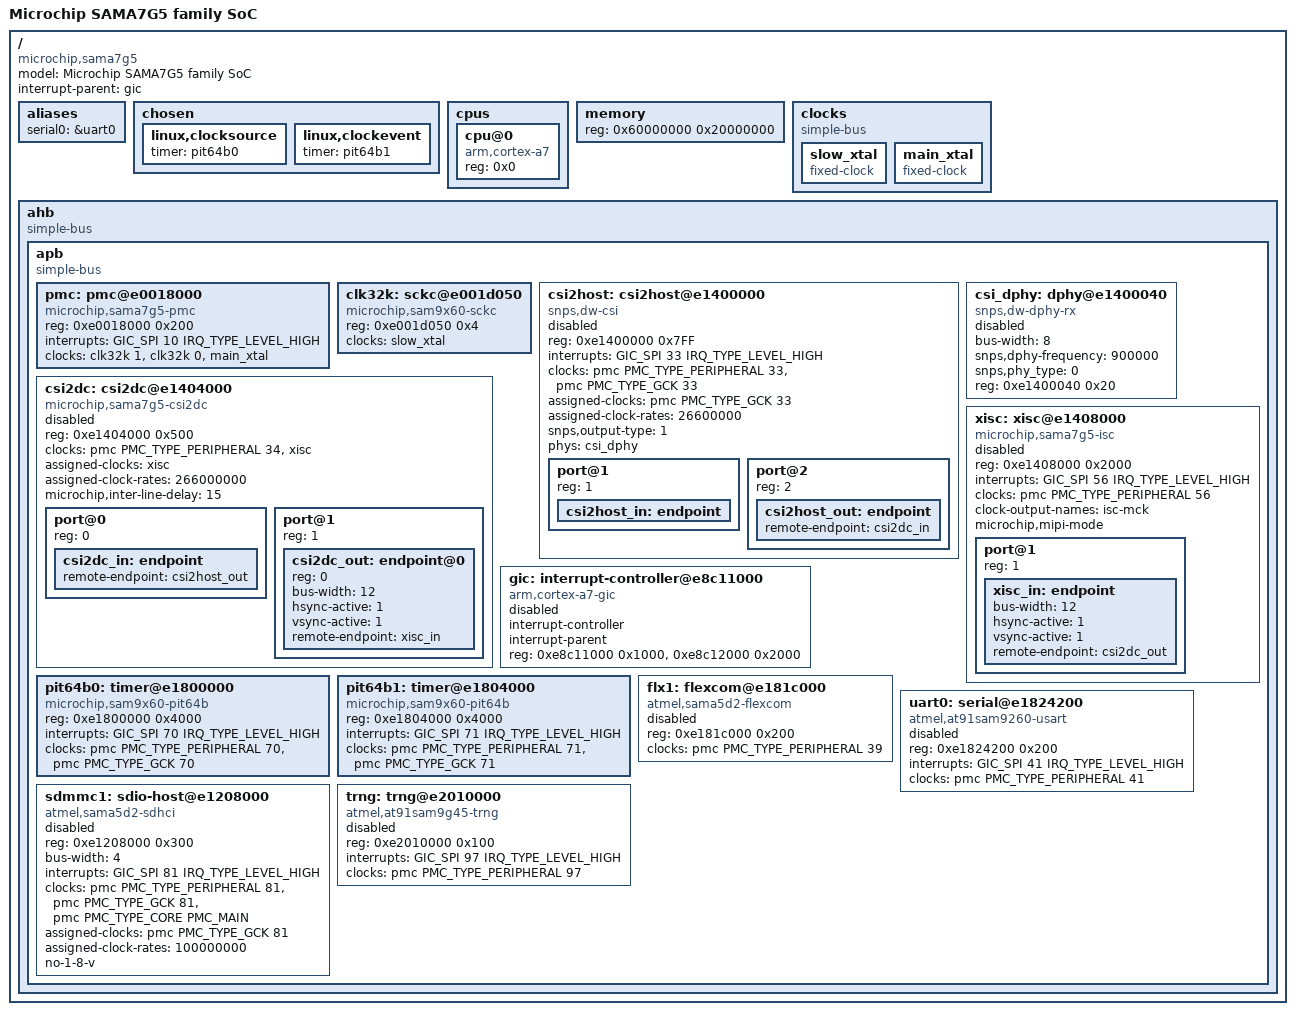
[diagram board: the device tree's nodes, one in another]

// SPDX-License-Identifier: (GPL-2.0+ OR MIT)
/*
 * sama7g5.dtsi - Device Tree Include file for SAMA7G5 family SoC
 *
 *  Copyright (C) 2020 Microchip Technology, Inc. and its subsidiaries
 *
 *  Author: Eugen Hristev <eugen.hristev@microchip.com>
 *
 */

#include <dt-bindings/interrupt-controller/irq.h>
#include <dt-bindings/interrupt-controller/arm-gic.h>
#include <dt-bindings/clock/at91.h>
#include <dt-bindings/dma/at91.h>
#include <dt-bindings/gpio/gpio.h>

/ {
	model = "Microchip SAMA7G5 family SoC";
	compatible = "microchip,sama7g5";
	#address-cells = <1>;
	#size-cells = <1>;
	interrupt-parent = <&gic>;

	aliases {
		serial0 = &uart0;
	};

	chosen {
		linux,clocksource {
			timer=<&pit64b0>;
		};

		linux,clockevent {
			timer=<&pit64b1>;
		};
	};

	cpus {
		#address-cells = <1>;
		#size-cells = <0>;

		cpu@0 {
			device_type = "cpu";
			compatible = "arm,cortex-a7";
			reg = <0x0>;
		};
	};

	/* 512 M */
	memory {
		device_type = "memory";
		reg = <0x60000000 0x20000000>;
	};

	clocks {
		compatible = "simple-bus";
		#address-cells = <1>;
		#size-cells = <0>;

		slow_xtal: slow_xtal {
			compatible = "fixed-clock";
			#clock-cells = <0>;
		};

		main_xtal: main_xtal {
			compatible = "fixed-clock";
			#clock-cells = <0>;
		};
	};

	ahb {
		compatible = "simple-bus";
		#address-cells = <1>;
		#size-cells = <1>;
		ranges;

		apb {
			compatible = "simple-bus";
			#address-cells = <1>;
			#size-cells = <1>;
			ranges;

			pmc: pmc@e0018000 {
				compatible = "microchip,sama7g5-pmc", "syscon";
				reg = <0xe0018000 0x200>;
				interrupts = <GIC_SPI 10 IRQ_TYPE_LEVEL_HIGH>;
				#clock-cells = <2>;
				clocks = <&clk32k 1>, <&clk32k 0>, <&main_xtal>;
				clock-names = "td_slck", "md_slck", "main_xtal";
			};

			clk32k: sckc@e001d050 {
				compatible = "microchip,sam9x60-sckc";
				reg = <0xe001d050 0x4>;
				clocks = <&slow_xtal>;
				#clock-cells = <1>;
			};

			csi2host: csi2host@e1400000 {
				compatible = "snps,dw-csi";
				#address-cells = <1>;
				#size-cells = <0>;
				reg = <0xe1400000 0x7FF>;
				interrupts = <GIC_SPI 33 IRQ_TYPE_LEVEL_HIGH>;
				clocks = <&pmc PMC_TYPE_PERIPHERAL 33>, <&pmc PMC_TYPE_GCK 33>;
				clock-names = "perclk", "phyclk";
				assigned-clocks = <&pmc PMC_TYPE_GCK 33>;
				assigned-clock-rates = <26600000>;
				snps,output-type = <1>;
				phys = <&csi_dphy>;
				status = "disabled";

				port@1 {
					reg = <1>;
					csi2host_in: endpoint {
					};
				};

				port@2 {
					reg = <2>;
					csi2host_out: endpoint {
						remote-endpoint = <&csi2dc_in>;
					};
				};
			};

			csi_dphy: dphy@e1400040 {
				compatible = "snps,dw-dphy-rx";
				#phy-cells = <0>;
				bus-width = <8>;
				snps,dphy-frequency = <900000>;
				snps,phy_type = <0>;
				reg = <0xe1400040 0x20>;
				status = "disabled";
			};

			csi2dc: csi2dc@e1404000 {
				compatible = "microchip,sama7g5-csi2dc";
				#address-cells = <1>;
				#size-cells = <0>;
				reg = <0xe1404000 0x500>;
				clocks = <&pmc PMC_TYPE_PERIPHERAL 34>, <&xisc>;
				clock-names = "pclk", "scck";
				assigned-clocks = <&xisc>;
				assigned-clock-rates = <266000000>;
				microchip,inter-line-delay = <15>;
				status = "disabled";

				port@0 {
					reg = <0>;
					csi2dc_in: endpoint {
						remote-endpoint = <&csi2host_out>;
					};
				};

				port@1 {
					#address-cells = <1>;
					#size-cells = <0>;
					reg = <1>;
					csi2dc_out: endpoint@0 {
						reg = <0>; /* VC 0 */
						bus-width = <12>;
						hsync-active = <1>;
						vsync-active = <1>;
						remote-endpoint = <&xisc_in>;
					};
				};
			};

			xisc: xisc@e1408000 {
				compatible = "microchip,sama7g5-isc";
				reg = <0xe1408000 0x2000>;
				interrupts = <GIC_SPI 56 IRQ_TYPE_LEVEL_HIGH>;
				#address-cells = <1>;
				#size-cells = <0>;
				clocks = <&pmc PMC_TYPE_PERIPHERAL 56>;
				clock-names = "hclock";
				#clock-cells = <0>;
				clock-output-names = "isc-mck";
				microchip,mipi-mode;
				status = "disabled";

				port@1 {
					reg = <1>;
					xisc_in: endpoint {
						bus-width = <12>;
						hsync-active = <1>;
						vsync-active = <1>;
						remote-endpoint = <&csi2dc_out>;
					};
				};
			};

			gic: interrupt-controller@e8c11000 {
				compatible = "arm,cortex-a7-gic";
				#interrupt-cells = <3>;
				#address-cells = <0>;
				interrupt-controller;
				interrupt-parent;
				reg = <0xe8c11000 0x1000>,
					<0xe8c12000 0x2000>;
				status = "disabled";
			};

			pit64b0: timer@e1800000 {
				compatible = "microchip,sam9x60-pit64b";
				reg = <0xe1800000 0x4000>;
				interrupts = <GIC_SPI 70 IRQ_TYPE_LEVEL_HIGH>;
				clocks = <&pmc PMC_TYPE_PERIPHERAL 70>, <&pmc PMC_TYPE_GCK 70>;
				clock-names = "pclk", "gclk";
				status = "okay";
			};

			pit64b1: timer@e1804000 {
				compatible = "microchip,sam9x60-pit64b";
				reg = <0xe1804000 0x4000>;
				interrupts = <GIC_SPI 71 IRQ_TYPE_LEVEL_HIGH>;
				clocks = <&pmc PMC_TYPE_PERIPHERAL 71>, <&pmc PMC_TYPE_GCK 71>;
				clock-names = "pclk", "gclk";
				status = "okay";
			};

			flx1: flexcom@e181c000 {
				compatible = "atmel,sama5d2-flexcom";
				reg = <0xe181c000 0x200>;
				clocks = <&pmc PMC_TYPE_PERIPHERAL 39>;
				#address-cells = <1>;
				#size-cells = <1>;
				ranges = <0x0 0xe181c000 0x800>;
				status = "disabled";
			};

			uart0: serial@e1824200 {
				compatible = "atmel,at91sam9260-usart";
				reg = <0xe1824200 0x200>;
				interrupts = <GIC_SPI 41 IRQ_TYPE_LEVEL_HIGH>;
				clocks = <&pmc PMC_TYPE_PERIPHERAL 41>;
				clock-names = "usart";
				status = "disabled";
			};

			sdmmc1: sdio-host@e1208000 {
				compatible = "atmel,sama5d2-sdhci";
				reg = <0xe1208000 0x300>;
				bus-width = <4>;
				interrupts = <GIC_SPI 81 IRQ_TYPE_LEVEL_HIGH>;
				clocks = <&pmc PMC_TYPE_PERIPHERAL 81>, <&pmc PMC_TYPE_GCK 81>, <&pmc PMC_TYPE_CORE PMC_MAIN>;
				clock-names = "hclock", "multclk", "baseclk";
				assigned-clocks = <&pmc PMC_TYPE_GCK 81>;
				assigned-clock-rates = <100000000>;
				no-1-8-v;
				status = "disabled";
			};

			trng: trng@e2010000 {
				compatible = "atmel,at91sam9g45-trng";
				reg = <0xe2010000 0x100>;
				interrupts = <GIC_SPI 97 IRQ_TYPE_LEVEL_HIGH>;
				clocks = <&pmc PMC_TYPE_PERIPHERAL 97>;
				status = "disabled";
			};
		};
	};
};
